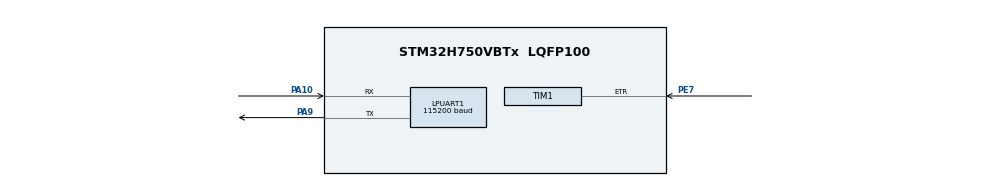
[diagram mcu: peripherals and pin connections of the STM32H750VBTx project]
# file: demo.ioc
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LPUART1.BaudRate=115200
Mcu.Family=STM32H7
Mcu.Name=STM32H750VBTx
Mcu.Package=LQFP100
NVIC.PriorityGroup=NVIC_PRIORITYGROUP_4
NVIC.TIM1_UP_IRQn=true\:1\:0\:true\:false\:true\:true\:true\:true
PA10.Mode=Asynchronous
PA10.Signal=LPUART1_RX
PA9.Mode=Asynchronous
PA9.Signal=LPUART1_TX
PC14-OSC32_IN\ (OSC32_IN).Mode=LSE-External-Oscillator
PC14-OSC32_IN\ (OSC32_IN).Signal=RCC_OSC32_IN
PC15-OSC32_OUT\ (OSC32_OUT).Mode=LSE-External-Oscillator
PC15-OSC32_OUT\ (OSC32_OUT).Signal=RCC_OSC32_OUT
PE7.Signal=S_TIM1_ETR
PH0-OSC_IN\ (PH0).Mode=HSE-External-Oscillator
PH0-OSC_IN\ (PH0).Signal=RCC_OSC_IN
PH1-OSC_OUT\ (PH1).Mode=HSE-External-Oscillator
PH1-OSC_OUT\ (PH1).Signal=RCC_OSC_OUT
ProjectManager.HeapSize=0x200
ProjectManager.StackSize=0x400
ProjectManager.TargetToolchain=MDK-ARM V5.32
RCC.ADCFreq_Value=129000000
RCC.APB1Freq_Value=64000000
RCC.APB2Freq_Value=32000000
RCC.APB3Freq_Value=32000000
RCC.APB4Freq_Value=64000000
RCC.CortexFreq_Value=64000000
RCC.D1PPRE=RCC_APB3_DIV2
RCC.D2PPRE2=RCC_APB2_DIV2
RCC.HCLKFreq_Value=64000000
RCC.SYSCLKFreq_VALUE=64000000
RCC.USBFreq_Value=129000000
SH.S_TIM1_ETR.0=TIM1_ETR,ClockSourceETR_Mode2
TIM1.AutoReloadPreload=TIM_AUTORELOAD_PRELOAD_ENABLE
TIM1.ClockPolarity=TIM_CLOCKPOLARITY_NONINVERTED
TIM1.ClockPrescaler=TIM_CLOCKPRESCALER_DIV1
TIM1.Period=1000
TIM1.Prescaler=10
board=custom

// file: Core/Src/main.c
/* USER CODE BEGIN Header */
/**
  ******************************************************************************
  * @file           : main.c
  * @brief          : Main program body
  ******************************************************************************
  * @attention
  *
  * Copyright (c) 2023 STMicroelectronics.
  * All rights reserved.
  *
  * This software is licensed under terms that can be found in the LICENSE file
  * in the root directory of this software component.
  * If no LICENSE file comes with this software, it is provided AS-IS.
  *
  ******************************************************************************
  */
/* USER CODE END Header */
#include "main.h"
#include "usart.h"
#include "tim.h"
#include "gpio.h"

/* USER CODE BEGIN Includes */
#include "stdio.h"
/* USER CODE END Includes */

void SystemClock_Config(void);

int main(void)
{

  /* MCU Configuration--------------------------------------------------------*/

  /* Reset of all peripherals, Initializes the Flash interface and the Systick. */
  HAL_Init();

  /* Configure the system clock */
  SystemClock_Config();

  /* Initialize all configured peripherals */
  MX_GPIO_Init();
  MX_LPUART1_UART_Init();
  MX_TIM1_Init();
  /* USER CODE BEGIN 2 */
		printf("%s\r\n", "hello");
		HAL_Delay(100);
		HAL_TIM_Base_Start_IT(&htim1);

  /* USER CODE END 2 */

  /* Infinite loop */
  while (1)
  {

  }
}

void SystemClock_Config(void)
{
  RCC_OscInitTypeDef RCC_OscInitStruct = {0};
  RCC_ClkInitTypeDef RCC_ClkInitStruct = {0};

  /** Supply configuration update enable
  */
  HAL_PWREx_ConfigSupply(PWR_LDO_SUPPLY);

  /** Configure the main internal regulator output voltage
  */
  __HAL_PWR_VOLTAGESCALING_CONFIG(PWR_REGULATOR_VOLTAGE_SCALE3);

  while(!__HAL_PWR_GET_FLAG(PWR_FLAG_VOSRDY)) {}

  /** Initializes the RCC Oscillators according to the specified parameters
  * in the RCC_OscInitTypeDef structure.
  */
  RCC_OscInitStruct.OscillatorType = RCC_OSCILLATORTYPE_HSI;
  RCC_OscInitStruct.HSIState = RCC_HSI_DIV1;
  RCC_OscInitStruct.HSICalibrationValue = RCC_HSICALIBRATION_DEFAULT;
  RCC_OscInitStruct.PLL.PLLState = RCC_PLL_NONE;
  if (HAL_RCC_OscConfig(&RCC_OscInitStruct) != HAL_OK)
  {
    Error_Handler();
  }

  /** Initializes the CPU, AHB and APB buses clocks
  */
  RCC_ClkInitStruct.ClockType = RCC_CLOCKTYPE_HCLK|RCC_CLOCKTYPE_SYSCLK
                              |RCC_CLOCKTYPE_PCLK1|RCC_CLOCKTYPE_PCLK2
                              |RCC_CLOCKTYPE_D3PCLK1|RCC_CLOCKTYPE_D1PCLK1;
  RCC_ClkInitStruct.SYSCLKSource = RCC_SYSCLKSOURCE_HSI;
  RCC_ClkInitStruct.SYSCLKDivider = RCC_SYSCLK_DIV1;
  RCC_ClkInitStruct.AHBCLKDivider = RCC_HCLK_DIV1;
  RCC_ClkInitStruct.APB3CLKDivider = RCC_APB3_DIV2;
  RCC_ClkInitStruct.APB1CLKDivider = RCC_APB1_DIV1;
  RCC_ClkInitStruct.APB2CLKDivider = RCC_APB2_DIV2;
  RCC_ClkInitStruct.APB4CLKDivider = RCC_APB4_DIV1;

  if (HAL_RCC_ClockConfig(&RCC_ClkInitStruct, FLASH_LATENCY_1) != HAL_OK)
  {
    Error_Handler();
  }
}

void Error_Handler(void)
{
  __disable_irq();
  while (1)
  {
  }
}
